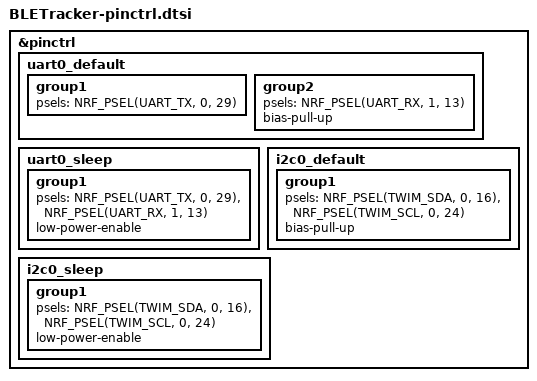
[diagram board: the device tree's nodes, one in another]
/*
 * Copyright (C) 2026 Lancelot MEI
 * SPDX-License-Identifier: GPL-2.0-only
 *
 * Pin control configuration for BLETracker
 */

#include <zephyr/dt-bindings/pinctrl/nrf-pinctrl.h>

&pinctrl {
    /* UART0 ：RXD=P1.13, TXD=P0.29 */
    uart0_default: uart0_default {
        group1 {
            psels = <NRF_PSEL(UART_TX, 0, 29)>;
        };
        group2 {
            psels = <NRF_PSEL(UART_RX, 1, 13)>;
            bias-pull-up;
        };
    };

    uart0_sleep: uart0_sleep {
        group1 {
            psels = <NRF_PSEL(UART_TX, 0, 29)>,
                    <NRF_PSEL(UART_RX, 1, 13)>;
            low-power-enable;
        };
    };

    /* I2C0 ：SDA=P0.16, SCL=P0.24 */
    i2c0_default: i2c0_default {
        group1 {
            psels = <NRF_PSEL(TWIM_SDA, 0, 16)>,
                    <NRF_PSEL(TWIM_SCL, 0, 24)>;
            bias-pull-up; /* I2C pull up for M10 */
        };
    };

    i2c0_sleep: i2c0_sleep {
        group1 {
            psels = <NRF_PSEL(TWIM_SDA, 0, 16)>,
                    <NRF_PSEL(TWIM_SCL, 0, 24)>;
            low-power-enable;
        };
    };
};
